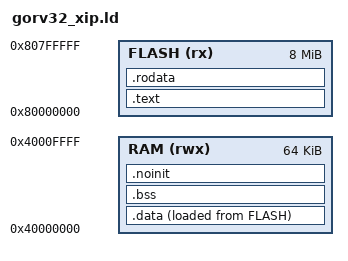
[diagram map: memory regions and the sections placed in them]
OUTPUT_FORMAT("elf32-littleriscv", "elf32-littleriscv", "elf32-littleriscv")
OUTPUT_ARCH(riscv)
ENTRY(crtStart)

MEMORY
{
    FLASH (rx)  : ORIGIN = 0x80000000, LENGTH = 8M
    RAM   (rwx) : ORIGIN = 0x40000000, LENGTH = 64K
}

/* 启动/中断共用的机器栈固定保留在 RAM 顶部。 */
__machine_stack_size = 2K;
_sp = ORIGIN(RAM) + LENGTH(RAM);
__machine_stack_bottom = _sp - __machine_stack_size;

SECTIONS
{
    .text :
    {
        . = ALIGN(4);
        KEEP(*(.text.entry))
        *(.text .text.*)
        *(.gnu.linkonce.t.*)

        . = ALIGN(4);
        __fsymtab_start = .;
        KEEP(*(FSymTab))
        __fsymtab_end = .;

        . = ALIGN(4);
        __vsymtab_start = .;
        KEEP(*(VSymTab))
        __vsymtab_end = .;

        . = ALIGN(4);
        __rt_init_start = .;
        KEEP(*(SORT(.rti_fn*)))
        __rt_init_end = .;
    } > FLASH

    .rodata :
    {
        . = ALIGN(4);
        *(.rdata .rdata.*)
        *(.rodata .rodata.*)
        *(.srodata .srodata.*)
        *(.gnu.linkonce.r.*)

        . = ALIGN(4);
        PROVIDE_HIDDEN(__preinit_array_start = .);
        KEEP(*(.preinit_array))
        PROVIDE_HIDDEN(__preinit_array_end = .);

        . = ALIGN(4);
        PROVIDE_HIDDEN(__init_array_start = .);
        KEEP(*(SORT_BY_INIT_PRIORITY(.init_array.*)))
        KEEP(*(.init_array))
        PROVIDE_HIDDEN(__init_array_end = .);

        . = ALIGN(4);
        PROVIDE_HIDDEN(__fini_array_start = .);
        KEEP(*(SORT_BY_INIT_PRIORITY(.fini_array.*)))
        KEEP(*(.fini_array))
        PROVIDE_HIDDEN(__fini_array_end = .);
    } > FLASH

    .data :
    {
        . = ALIGN(8);
        __data_start = .;
        *(.data .data.*)
        *(.gnu.linkonce.d.*)
        . = ALIGN(8);
        PROVIDE(__global_pointer$ = . + 0x800);
        *(.sdata .sdata.*)
        *(.gnu.linkonce.s.*)
        . = ALIGN(4);
        __data_end = .;
    } > RAM AT > FLASH
    __data_load = LOADADDR(.data);

    .bss (NOLOAD) :
    {
        . = ALIGN(8);
        __bss_start = .;
        *(.sbss .sbss.*)
        *(.gnu.linkonce.sb.*)
        *(.bss .bss.*)
        *(.gnu.linkonce.b.*)
        *(COMMON)
        . = ALIGN(8);
        __bss_end = .;
    } > RAM

    .noinit (NOLOAD) :
    {
        . = ALIGN(8);
        *(.noinit .noinit.*)
        . = ALIGN(8);
        __ram_static_end = .;
    } > RAM

    /DISCARD/ :
    {
        *(.comment)
        *(.note*)
        *(.eh_frame*)
    }

    ASSERT(__ram_static_end <= __machine_stack_bottom,
           "GoRV32 64 KiB RAM overflow: static data overlaps machine stack")
}
